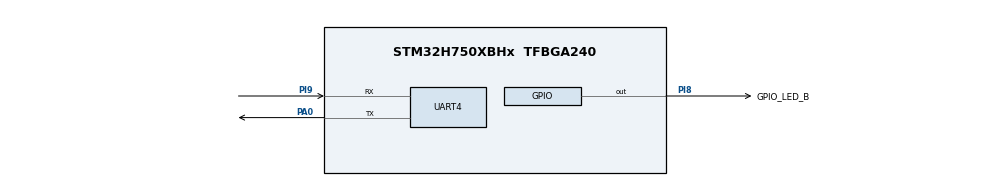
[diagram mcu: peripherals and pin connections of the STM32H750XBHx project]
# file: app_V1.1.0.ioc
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CORTEX_M7.AccessPermission_Spec=MPU_REGION_FULL_ACCESS
CORTEX_M7.BaseAddress_Spec=0x90000000
CORTEX_M7.DisableExec_Spec=MPU_INSTRUCTION_ACCESS_ENABLE
CORTEX_M7.Enable-Cortex_Memory_Protection_Unit_Region0_Settings=MPU_REGION_ENABLE
CORTEX_M7.IsBufferable_Spec=MPU_ACCESS_BUFFERABLE
CORTEX_M7.IsCacheable_Spec=MPU_ACCESS_CACHEABLE
CORTEX_M7.IsShareable_Spec=MPU_ACCESS_NOT_SHAREABLE
CORTEX_M7.MPU_Control=__NULL
CORTEX_M7.Size_Spec=MPU_REGION_SIZE_256MB
CORTEX_M7.SubRegionDisable_Spec=0x0
CORTEX_M7.TypeExtField_Spec=MPU_TEX_LEVEL1
CORTEX_M7.default_mode_Activation=0
Mcu.Family=STM32H7
Mcu.Name=STM32H750XBHx
Mcu.Package=TFBGA240
NVIC.PriorityGroup=NVIC_PRIORITYGROUP_4
PA0.Mode=Asynchronous
PA0.Signal=UART4_TX
PA13\ (JTMS/SWDIO).Mode=Serial_Wire
PA13\ (JTMS/SWDIO).Signal=DEBUG_JTMS-SWDIO
PA14\ (JTCK/SWCLK).Mode=Serial_Wire
PA14\ (JTCK/SWCLK).Signal=DEBUG_JTCK-SWCLK
PC14-OSC32_IN\ (OSC32_IN).Mode=LSE-External-Oscillator
PC14-OSC32_IN\ (OSC32_IN).Signal=RCC_OSC32_IN
PC15-OSC32_OUT\ (OSC32_OUT).Mode=LSE-External-Oscillator
PC15-OSC32_OUT\ (OSC32_OUT).Signal=RCC_OSC32_OUT
PH0-OSC_IN\ (PH0).Mode=HSE-External-Oscillator
PH0-OSC_IN\ (PH0).Signal=RCC_OSC_IN
PH1-OSC_OUT\ (PH1).Mode=HSE-External-Oscillator
PH1-OSC_OUT\ (PH1).Signal=RCC_OSC_OUT
PH5.Signal=FMC_SDNWE
PI8.GPIO_Label=GPIO_LED_B
PI8.Signal=GPIO_Output
PI9.Mode=Asynchronous
PI9.Signal=UART4_RX
ProjectManager.HeapSize=0x400
ProjectManager.StackSize=0x400
ProjectManager.TargetToolchain=Makefile
RCC.ADCFreq_Value=109375000
RCC.APB1Freq_Value=120000000
RCC.APB2Freq_Value=120000000
RCC.APB3Freq_Value=120000000
RCC.APB4Freq_Value=120000000
RCC.CortexFreq_Value=480000000
RCC.D1PPRE=RCC_APB3_DIV2
RCC.D2PPRE1=RCC_APB1_DIV2
RCC.D2PPRE2=RCC_APB2_DIV2
RCC.D3PPRE=RCC_APB4_DIV2
RCC.DIVM1=5
RCC.DIVM2=4
RCC.DIVN1=192
RCC.DIVN2=35
RCC.DIVQ1=4
RCC.HCLKFreq_Value=240000000
RCC.HPRE=RCC_HCLK_DIV2
RCC.PLL2FRACN=0
RCC.PLL3FRACN=0
RCC.PLLFRACN=0
RCC.PLLSourceVirtual=RCC_PLLSOURCE_HSE
RCC.PWR_Regulator_Voltage_Scale=PWR_REGULATOR_VOLTAGE_SCALE0
RCC.ProductRev=revV
RCC.SYSCLKFreq_VALUE=480000000
RCC.SYSCLKSource=RCC_SYSCLKSOURCE_PLLCLK
RCC.SupplySource=PWR_LDO_SUPPLY
RCC.USBFreq_Value=240000000
SH.FMC_SDNWE.0=FMC_SDNWE
board=custom

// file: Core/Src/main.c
/* USER CODE BEGIN Header */
/**
  ******************************************************************************
  * @file           : main.c
  * @brief          : Main program body
  ******************************************************************************
  * @attention
  *
  * Copyright (c) 2023 STMicroelectronics.
  * All rights reserved.
  *
  * This software is licensed under terms that can be found in the LICENSE file
  * in the root directory of this software component.
  * If no LICENSE file comes with this software, it is provided AS-IS.
  *
  ******************************************************************************
  */
/* USER CODE END Header */
#include "main.h"
#include "usart.h"
#include "gpio.h"

/* USER CODE BEGIN Includes */
#include <stdio.h>
#include <string.h>

int _write(int fd, char *ch, int len)
{
    HAL_UART_Transmit(&huart4, (uint8_t*)ch, len, 0xFFFF);
    return len;
}
/* USER CODE END Includes */

void SystemClock_Config(void);

/* USER CODE BEGIN 0 */
__attribute__((section(".sdram")))	uint32_t test[4096] = {0}; //sdram有问�??
static uint32_t test2[4096];
/* USER CODE END 0 */

int main(void)
{
  /* USER CODE BEGIN 1 */
    SCB->VTOR = QSPI_BASE;		// 重定位中断向量表
    __enable_irq();
  /* USER CODE END 1 */

  /* MCU Configuration--------------------------------------------------------*/

  /* Reset of all peripherals, Initializes the Flash interface and the Systick. */
  HAL_Init();

  /* Configure the system clock */
  SystemClock_Config();

  /* Initialize all configured peripherals */
  MX_GPIO_Init();
  MX_UART4_Init();
  /* USER CODE BEGIN 2 */
    memset((uint32_t*)(0xc0000000),0xff,32*1024*1024);

  /* USER CODE END 2 */

  /* Infinite loop */
  /* USER CODE BEGIN WHILE */
  while (1)
  {
      HAL_GPIO_TogglePin(GPIO_LED_B_GPIO_Port,GPIO_LED_B_Pin);

      HAL_Delay(500);
//      printf("app running : %04d\r\n",j);

    /* USER CODE END WHILE */

  }
}

void SystemClock_Config(void)
{
  RCC_OscInitTypeDef RCC_OscInitStruct = {0};
  RCC_ClkInitTypeDef RCC_ClkInitStruct = {0};

  /** Supply configuration update enable
  */
  HAL_PWREx_ConfigSupply(PWR_LDO_SUPPLY);

  /** Configure the main internal regulator output voltage
  */
  __HAL_PWR_VOLTAGESCALING_CONFIG(PWR_REGULATOR_VOLTAGE_SCALE1);

  while(!__HAL_PWR_GET_FLAG(PWR_FLAG_VOSRDY)) {}

  __HAL_RCC_SYSCFG_CLK_ENABLE();
  __HAL_PWR_VOLTAGESCALING_CONFIG(PWR_REGULATOR_VOLTAGE_SCALE0);

  while(!__HAL_PWR_GET_FLAG(PWR_FLAG_VOSRDY)) {}

  /** Initializes the RCC Oscillators according to the specified parameters
  * in the RCC_OscInitTypeDef structure.
  */
  RCC_OscInitStruct.OscillatorType = RCC_OSCILLATORTYPE_HSE;
  RCC_OscInitStruct.HSEState = RCC_HSE_ON;
  RCC_OscInitStruct.PLL.PLLState = RCC_PLL_ON;
  RCC_OscInitStruct.PLL.PLLSource = RCC_PLLSOURCE_HSE;
  RCC_OscInitStruct.PLL.PLLM = 5;
  RCC_OscInitStruct.PLL.PLLN = 192;
  RCC_OscInitStruct.PLL.PLLP = 2;
  RCC_OscInitStruct.PLL.PLLQ = 4;
  RCC_OscInitStruct.PLL.PLLR = 2;
  RCC_OscInitStruct.PLL.PLLRGE = RCC_PLL1VCIRANGE_2;
  RCC_OscInitStruct.PLL.PLLVCOSEL = RCC_PLL1VCOWIDE;
  RCC_OscInitStruct.PLL.PLLFRACN = 0;
  if (HAL_RCC_OscConfig(&RCC_OscInitStruct) != HAL_OK)
  {
    Error_Handler();
  }

  /** Initializes the CPU, AHB and APB buses clocks
  */
  RCC_ClkInitStruct.ClockType = RCC_CLOCKTYPE_HCLK|RCC_CLOCKTYPE_SYSCLK
                              |RCC_CLOCKTYPE_PCLK1|RCC_CLOCKTYPE_PCLK2
                              |RCC_CLOCKTYPE_D3PCLK1|RCC_CLOCKTYPE_D1PCLK1;
  RCC_ClkInitStruct.SYSCLKSource = RCC_SYSCLKSOURCE_PLLCLK;
  RCC_ClkInitStruct.SYSCLKDivider = RCC_SYSCLK_DIV1;
  RCC_ClkInitStruct.AHBCLKDivider = RCC_HCLK_DIV2;
  RCC_ClkInitStruct.APB3CLKDivider = RCC_APB3_DIV2;
  RCC_ClkInitStruct.APB1CLKDivider = RCC_APB1_DIV2;
  RCC_ClkInitStruct.APB2CLKDivider = RCC_APB2_DIV2;
  RCC_ClkInitStruct.APB4CLKDivider = RCC_APB4_DIV2;

  if (HAL_RCC_ClockConfig(&RCC_ClkInitStruct, FLASH_LATENCY_4) != HAL_OK)
  {
    Error_Handler();
  }
}

void Error_Handler(void)
{
  __disable_irq();
  while (1)
  {
  }
}
